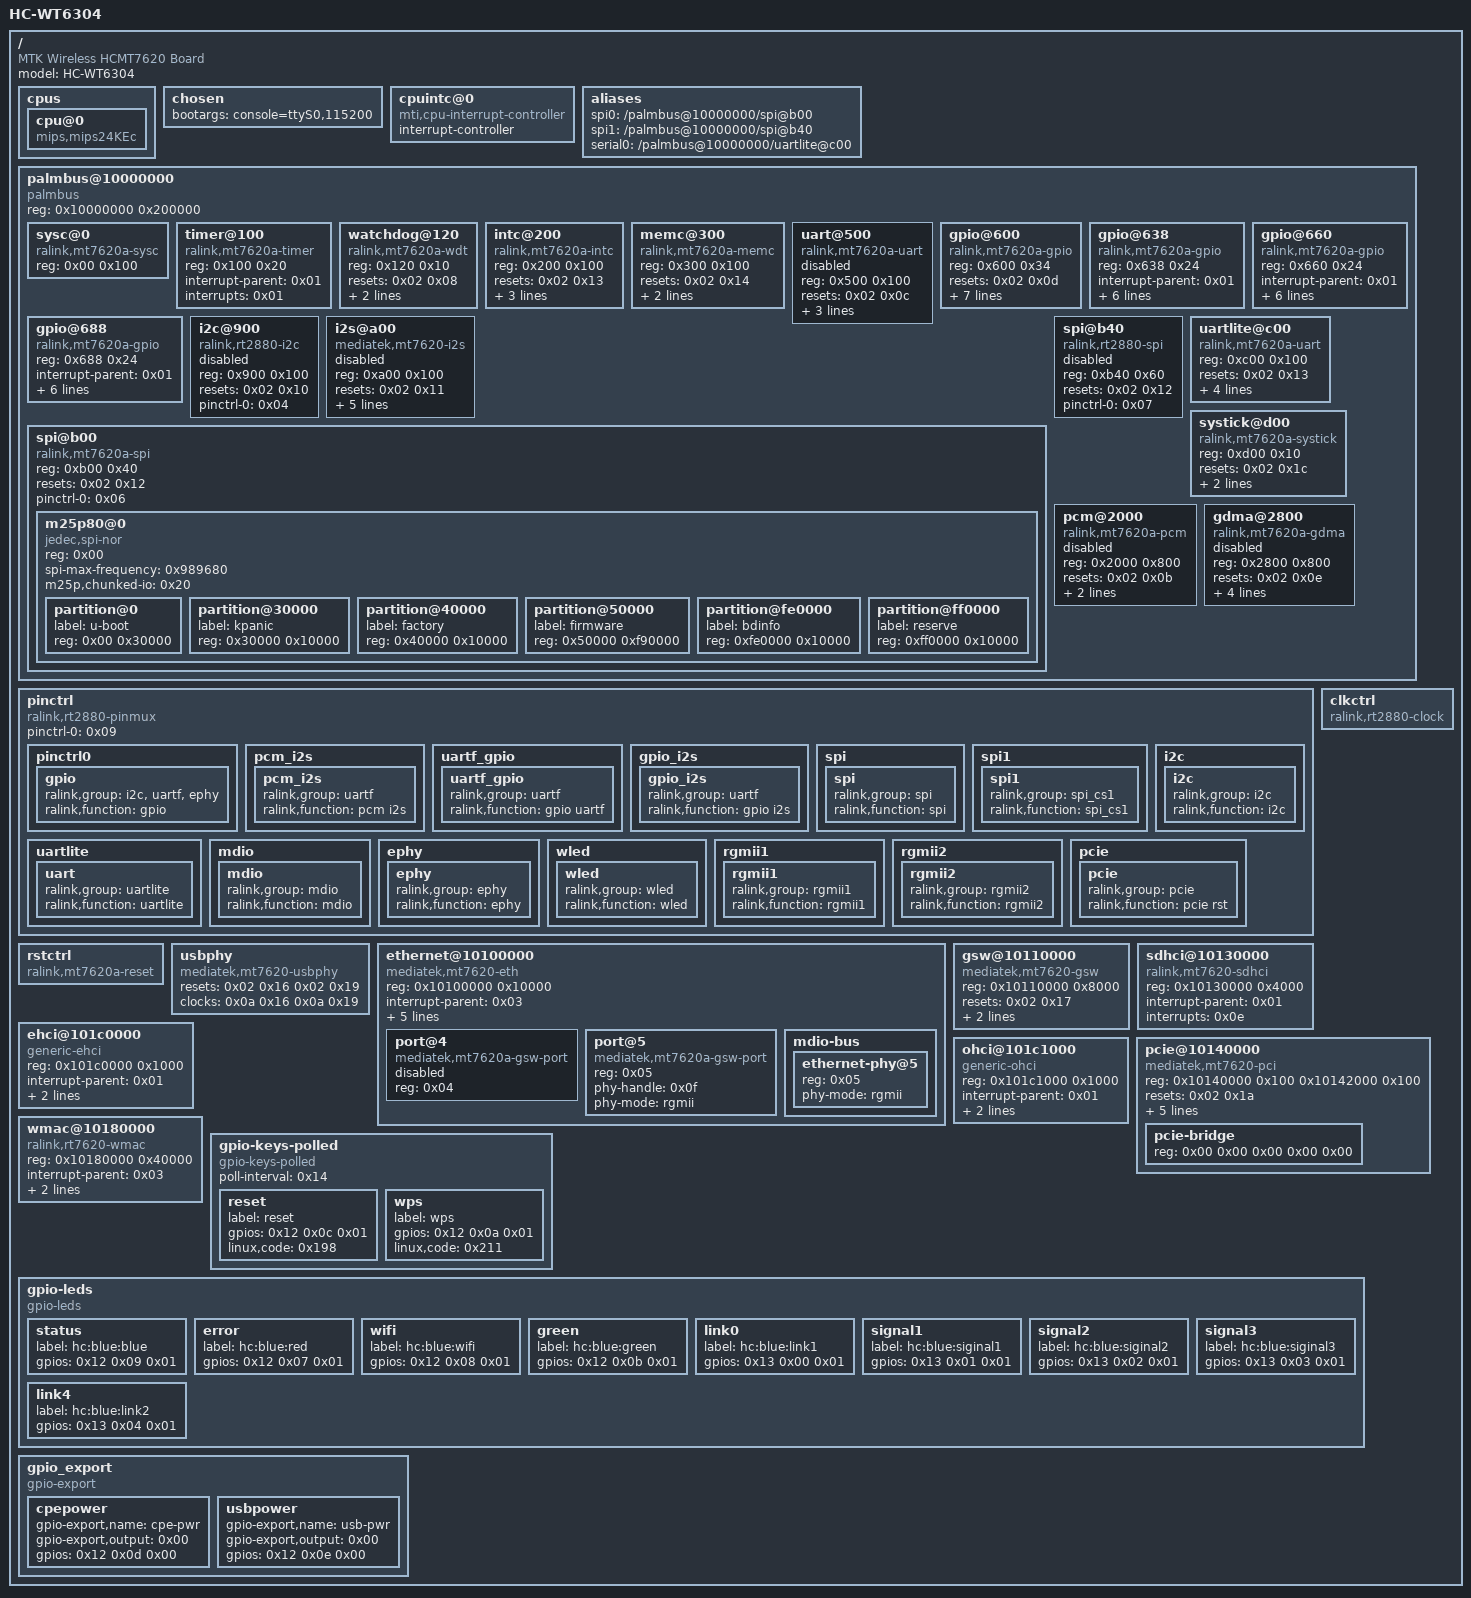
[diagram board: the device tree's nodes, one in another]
/dts-v1/;

/ {
	#address-cells = <0x01>;
	#size-cells = <0x01>;
	compatible = "MTK Wireless HCMT7620 Board", "ralink,mt7620a-soc";
	model = "HC-WT6304";

	cpus {

		cpu@0 {
			compatible = "mips,mips24KEc";
		};
	};

	chosen {
		bootargs = "console=ttyS0,115200";
	};

	cpuintc@0 {
		#address-cells = <0x00>;
		#interrupt-cells = <0x01>;
		interrupt-controller;
		compatible = "mti,cpu-interrupt-controller";
		linux,phandle = <0x03>;
		phandle = <0x03>;
	};

	aliases {
		spi0 = "/palmbus@10000000/spi@b00";
		spi1 = "/palmbus@10000000/spi@b40";
		serial0 = "/palmbus@10000000/uartlite@c00";
	};

	palmbus@10000000 {
		compatible = "palmbus";
		reg = <0x10000000 0x200000>;
		ranges = <0x00 0x10000000 0x1fffff>;
		#address-cells = <0x01>;
		#size-cells = <0x01>;

		sysc@0 {
			compatible = "ralink,mt7620a-sysc", "ralink,rt3050-sysc";
			reg = <0x00 0x100>;
		};

		timer@100 {
			compatible = "ralink,mt7620a-timer", "ralink,rt2880-timer";
			reg = <0x100 0x20>;
			interrupt-parent = <0x01>;
			interrupts = <0x01>;
		};

		watchdog@120 {
			compatible = "ralink,mt7620a-wdt", "ralink,rt2880-wdt";
			reg = <0x120 0x10>;
			resets = <0x02 0x08>;
			reset-names = "wdt";
			interrupt-parent = <0x01>;
			interrupts = <0x01>;
		};

		intc@200 {
			compatible = "ralink,mt7620a-intc", "ralink,rt2880-intc";
			reg = <0x200 0x100>;
			resets = <0x02 0x13>;
			reset-names = "intc";
			interrupt-controller;
			#interrupt-cells = <0x01>;
			interrupt-parent = <0x03>;
			interrupts = <0x02>;
			linux,phandle = <0x01>;
			phandle = <0x01>;
		};

		memc@300 {
			compatible = "ralink,mt7620a-memc", "ralink,rt3050-memc";
			reg = <0x300 0x100>;
			resets = <0x02 0x14>;
			reset-names = "mc";
			interrupt-parent = <0x01>;
			interrupts = <0x03>;
		};

		uart@500 {
			compatible = "ralink,mt7620a-uart", "ralink,rt2880-uart", "ns16550a";
			reg = <0x500 0x100>;
			resets = <0x02 0x0c>;
			reset-names = "uart";
			interrupt-parent = <0x01>;
			interrupts = <0x05>;
			reg-shift = <0x02>;
			status = "disabled";
		};

		gpio@600 {
			compatible = "ralink,mt7620a-gpio", "ralink,rt2880-gpio";
			reg = <0x600 0x34>;
			resets = <0x02 0x0d>;
			reset-names = "pio";
			interrupt-parent = <0x01>;
			interrupts = <0x06>;
			gpio-controller;
			#gpio-cells = <0x02>;
			ralink,gpio-base = <0x00>;
			ralink,num-gpios = <0x18>;
			ralink,register-map = [00 04 08 0c 20 24 28 2c 30 34];
			status = "okay";
			linux,phandle = <0x12>;
			phandle = <0x12>;
		};

		gpio@638 {
			compatible = "ralink,mt7620a-gpio", "ralink,rt2880-gpio";
			reg = <0x638 0x24>;
			interrupt-parent = <0x01>;
			interrupts = <0x06>;
			gpio-controller;
			#gpio-cells = <0x02>;
			ralink,gpio-base = <0x18>;
			ralink,num-gpios = <0x10>;
			ralink,register-map = [00 04 08 0c 10 14 18 1c 20 24];
			status = "okay";
		};

		gpio@660 {
			compatible = "ralink,mt7620a-gpio", "ralink,rt2880-gpio";
			reg = <0x660 0x24>;
			interrupt-parent = <0x01>;
			interrupts = <0x06>;
			gpio-controller;
			#gpio-cells = <0x02>;
			ralink,gpio-base = <0x28>;
			ralink,num-gpios = <0x20>;
			ralink,register-map = [00 04 08 0c 10 14 18 1c 20 24];
			status = "okay";
			linux,phandle = <0x13>;
			phandle = <0x13>;
		};

		gpio@688 {
			compatible = "ralink,mt7620a-gpio", "ralink,rt2880-gpio";
			reg = <0x688 0x24>;
			interrupt-parent = <0x01>;
			interrupts = <0x06>;
			gpio-controller;
			#gpio-cells = <0x02>;
			ralink,gpio-base = <0x48>;
			ralink,num-gpios = <0x01>;
			ralink,register-map = [00 04 08 0c 10 14 18 1c 20 24];
			status = "okay";
		};

		i2c@900 {
			compatible = "ralink,rt2880-i2c";
			reg = <0x900 0x100>;
			resets = <0x02 0x10>;
			reset-names = "i2c";
			#address-cells = <0x01>;
			#size-cells = <0x00>;
			status = "disabled";
			pinctrl-names = "default";
			pinctrl-0 = <0x04>;
		};

		i2s@a00 {
			compatible = "mediatek,mt7620-i2s";
			reg = <0xa00 0x100>;
			resets = <0x02 0x11>;
			reset-names = "i2s";
			interrupt-parent = <0x01>;
			interrupts = <0x0a>;
			txdma-req = <0x02>;
			rxdma-req = <0x03>;
			dmas = <0x05 0x04 0x05 0x06>;
			dma-names = "tx", "rx";
			status = "disabled";
		};

		spi@b00 {
			compatible = "ralink,mt7620a-spi", "ralink,rt2880-spi";
			reg = <0xb00 0x40>;
			resets = <0x02 0x12>;
			reset-names = "spi";
			#address-cells = <0x01>;
			#size-cells = <0x00>;
			status = "okay";
			pinctrl-names = "default";
			pinctrl-0 = <0x06>;

			m25p80@0 {
				#address-cells = <0x01>;
				#size-cells = <0x01>;
				compatible = "jedec,spi-nor";
				reg = <0x00>;
				spi-max-frequency = <0x989680>;
				m25p,chunked-io = <0x20>;

				partition@0 {
					label = "u-boot";
					reg = <0x00 0x30000>;
				};

				partition@30000 {
					label = "kpanic";
					reg = <0x30000 0x10000>;
				};

				partition@40000 {
					label = "factory";
					reg = <0x40000 0x10000>;
				};

				partition@50000 {
					label = "firmware";
					reg = <0x50000 0xf90000>;
				};

				partition@fe0000 {
					label = "bdinfo";
					reg = <0xfe0000 0x10000>;
					linux,phandle = <0x0c>;
					phandle = <0x0c>;
				};

				partition@ff0000 {
					label = "reserve";
					reg = <0xff0000 0x10000>;
				};
			};
		};

		spi@b40 {
			compatible = "ralink,rt2880-spi";
			reg = <0xb40 0x60>;
			resets = <0x02 0x12>;
			reset-names = "spi";
			#address-cells = <0x01>;
			#size-cells = <0x00>;
			status = "disabled";
			pinctrl-names = "default";
			pinctrl-0 = <0x07>;
		};

		uartlite@c00 {
			compatible = "ralink,mt7620a-uart", "ralink,rt2880-uart", "ns16550a";
			reg = <0xc00 0x100>;
			resets = <0x02 0x13>;
			reset-names = "uartl";
			interrupt-parent = <0x01>;
			interrupts = <0x0c>;
			reg-shift = <0x02>;
			pinctrl-names = "default";
			pinctrl-0 = <0x08>;
		};

		systick@d00 {
			compatible = "ralink,mt7620a-systick", "ralink,cevt-systick";
			reg = <0xd00 0x10>;
			resets = <0x02 0x1c>;
			reset-names = "intc";
			interrupt-parent = <0x03>;
			interrupts = <0x07>;
		};

		pcm@2000 {
			compatible = "ralink,mt7620a-pcm";
			reg = <0x2000 0x800>;
			resets = <0x02 0x0b>;
			reset-names = "pcm";
			interrupt-parent = <0x01>;
			interrupts = <0x04>;
			status = "disabled";
		};

		gdma@2800 {
			compatible = "ralink,mt7620a-gdma", "ralink,rt3883-gdma";
			reg = <0x2800 0x800>;
			resets = <0x02 0x0e>;
			reset-names = "dma";
			interrupt-parent = <0x01>;
			interrupts = <0x07>;
			#dma-cells = <0x01>;
			#dma-channels = <0x10>;
			#dma-requests = <0x10>;
			status = "disabled";
			linux,phandle = <0x05>;
			phandle = <0x05>;
		};
	};

	pinctrl {
		compatible = "ralink,rt2880-pinmux";
		pinctrl-names = "default";
		pinctrl-0 = <0x09>;

		pinctrl0 {
			linux,phandle = <0x09>;
			phandle = <0x09>;

			gpio {
				ralink,group = "i2c", "uartf", "ephy";
				ralink,function = "gpio";
			};
		};

		pcm_i2s {

			pcm_i2s {
				ralink,group = "uartf";
				ralink,function = "pcm i2s";
			};
		};

		uartf_gpio {

			uartf_gpio {
				ralink,group = "uartf";
				ralink,function = "gpio uartf";
			};
		};

		gpio_i2s {

			gpio_i2s {
				ralink,group = "uartf";
				ralink,function = "gpio i2s";
			};
		};

		spi {
			linux,phandle = <0x06>;
			phandle = <0x06>;

			spi {
				ralink,group = "spi";
				ralink,function = "spi";
			};
		};

		spi1 {
			linux,phandle = <0x07>;
			phandle = <0x07>;

			spi1 {
				ralink,group = "spi_cs1";
				ralink,function = "spi_cs1";
			};
		};

		i2c {
			linux,phandle = <0x04>;
			phandle = <0x04>;

			i2c {
				ralink,group = "i2c";
				ralink,function = "i2c";
			};
		};

		uartlite {
			linux,phandle = <0x08>;
			phandle = <0x08>;

			uart {
				ralink,group = "uartlite";
				ralink,function = "uartlite";
			};
		};

		mdio {
			linux,phandle = <0x0e>;
			phandle = <0x0e>;

			mdio {
				ralink,group = "mdio";
				ralink,function = "mdio";
			};
		};

		ephy {

			ephy {
				ralink,group = "ephy";
				ralink,function = "ephy";
			};
		};

		wled {

			wled {
				ralink,group = "wled";
				ralink,function = "wled";
			};
		};

		rgmii1 {
			linux,phandle = <0x0d>;
			phandle = <0x0d>;

			rgmii1 {
				ralink,group = "rgmii1";
				ralink,function = "rgmii1";
			};
		};

		rgmii2 {

			rgmii2 {
				ralink,group = "rgmii2";
				ralink,function = "rgmii2";
			};
		};

		pcie {
			linux,phandle = <0x11>;
			phandle = <0x11>;

			pcie {
				ralink,group = "pcie";
				ralink,function = "pcie rst";
			};
		};
	};

	rstctrl {
		compatible = "ralink,mt7620a-reset", "ralink,rt2880-reset";
		#reset-cells = <0x01>;
		linux,phandle = <0x02>;
		phandle = <0x02>;
	};

	clkctrl {
		compatible = "ralink,rt2880-clock";
		#clock-cells = <0x01>;
		linux,phandle = <0x0a>;
		phandle = <0x0a>;
	};

	usbphy {
		compatible = "mediatek,mt7620-usbphy";
		#phy-cells = <0x01>;
		resets = <0x02 0x16 0x02 0x19>;
		reset-names = "host", "device";
		clocks = <0x0a 0x16 0x0a 0x19>;
		clock-names = "host", "device";
		linux,phandle = <0x10>;
		phandle = <0x10>;
	};

	ethernet@10100000 {
		compatible = "mediatek,mt7620-eth";
		reg = <0x10100000 0x10000>;
		#address-cells = <0x01>;
		#size-cells = <0x00>;
		interrupt-parent = <0x03>;
		interrupts = <0x05>;
		resets = <0x02 0x15 0x02 0x17>;
		reset-names = "fe", "esw";
		mediatek,switch = <0x0b>;
		mtd-mac-address = <0x0c 0x09>;
		pinctrl-names = "default";
		pinctrl-0 = <0x0d 0x0e>;

		port@4 {
			compatible = "mediatek,mt7620a-gsw-port", "mediatek,eth-port";
			reg = <0x04>;
			status = "disabled";
		};

		port@5 {
			compatible = "mediatek,mt7620a-gsw-port", "mediatek,eth-port";
			reg = <0x05>;
			status = "okay";
			phy-handle = <0x0f>;
			phy-mode = "rgmii";
		};

		mdio-bus {
			#address-cells = <0x01>;
			#size-cells = <0x00>;
			status = "okay";

			ethernet-phy@5 {
				reg = <0x05>;
				phy-mode = "rgmii";
				linux,phandle = <0x0f>;
				phandle = <0x0f>;
			};
		};
	};

	gsw@10110000 {
		compatible = "mediatek,mt7620-gsw";
		reg = <0x10110000 0x8000>;
		resets = <0x02 0x17>;
		reset-names = "esw";
		interrupt-parent = <0x01>;
		interrupts = <0x11>;
		linux,phandle = <0x0b>;
		phandle = <0x0b>;
	};

	sdhci@10130000 {
		compatible = "ralink,mt7620-sdhci";
		reg = <0x10130000 0x4000>;
		interrupt-parent = <0x01>;
		interrupts = <0x0e>;
		status = "okay";
	};

	ehci@101c0000 {
		compatible = "generic-ehci";
		reg = <0x101c0000 0x1000>;
		interrupt-parent = <0x01>;
		interrupts = <0x12>;
		phys = <0x10 0x01>;
		phy-names = "usb";
		status = "okay";
	};

	ohci@101c1000 {
		compatible = "generic-ohci";
		reg = <0x101c1000 0x1000>;
		interrupt-parent = <0x01>;
		interrupts = <0x12>;
		phys = <0x10 0x01>;
		phy-names = "usb";
		status = "okay";
	};

	pcie@10140000 {
		compatible = "mediatek,mt7620-pci";
		reg = <0x10140000 0x100 0x10142000 0x100>;
		#address-cells = <0x03>;
		#size-cells = <0x02>;
		resets = <0x02 0x1a>;
		reset-names = "pcie0";
		clocks = <0x0a 0x1a>;
		clock-names = "pcie0";
		interrupt-parent = <0x03>;
		interrupts = <0x04>;
		pinctrl-names = "default";
		pinctrl-0 = <0x11>;
		device_type = "pci";
		bus-range = <0x00 0xff>;
		ranges = <0x2000000 0x00 0x00 0x20000000 0x00 0x10000000 0x1000000 0x00 0x00 0x10160000 0x00 0x10000>;
		status = "okay";

		pcie-bridge {
			reg = <0x00 0x00 0x00 0x00 0x00>;
			#address-cells = <0x03>;
			#size-cells = <0x02>;
			device_type = "pci";
		};
	};

	wmac@10180000 {
		compatible = "ralink,rt7620-wmac", "ralink,rt2880-wmac";
		reg = <0x10180000 0x40000>;
		interrupt-parent = <0x03>;
		interrupts = <0x06>;
		ralink,eeprom = "soc_wmac.eeprom";
	};

	gpio-keys-polled {
		compatible = "gpio-keys-polled";
		#address-cells = <0x01>;
		#size-cells = <0x00>;
		poll-interval = <0x14>;

		reset {
			label = "reset";
			gpios = <0x12 0x0c 0x01>;
			linux,code = <0x198>;
		};

		wps {
			label = "wps";
			gpios = <0x12 0x0a 0x01>;
			linux,code = <0x211>;
		};
	};

	gpio-leds {
		compatible = "gpio-leds";

		status {
			label = "hc:blue:blue";
			gpios = <0x12 0x09 0x01>;
		};

		error {
			label = "hc:blue:red";
			gpios = <0x12 0x07 0x01>;
		};

		wifi {
			label = "hc:blue:wifi";
			gpios = <0x12 0x08 0x01>;
		};

		green {
			label = "hc:blue:green";
			gpios = <0x12 0x0b 0x01>;
		};

		link0 {
			label = "hc:blue:link1";
			gpios = <0x13 0x00 0x01>;
		};

		signal1 {
			label = "hc:blue:siginal1";
			gpios = <0x13 0x01 0x01>;
		};

		signal2 {
			label = "hc:blue:siginal2";
			gpios = <0x13 0x02 0x01>;
		};

		signal3 {
			label = "hc:blue:siginal3";
			gpios = <0x13 0x03 0x01>;
		};

		link4 {
			label = "hc:blue:link2";
			gpios = <0x13 0x04 0x01>;
		};
	};

	gpio_export {
		compatible = "gpio-export";
		#size-cells = <0x00>;

		cpepower {
			gpio-export,name = "cpe-pwr";
			gpio-export,output = <0x00>;
			gpios = <0x12 0x0d 0x00>;
		};

		usbpower {
			gpio-export,name = "usb-pwr";
			gpio-export,output = <0x00>;
			gpios = <0x12 0x0e 0x00>;
		};
	};
};
